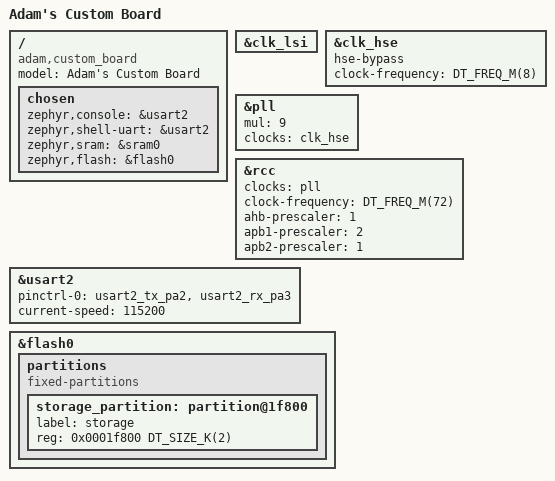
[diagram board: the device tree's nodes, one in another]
/dts-v1/;
#include <st/f1/stm32f103Xb.dtsi>
#include <st/f1/stm32f103r(8-b)tx-pinctrl.dtsi>
#include <zephyr/dt-bindings/input/input-event-codes.h>

/ {
	model = "Adam's Custom Board";
    compatible = "adam,custom_board";

	chosen {
        zephyr,console = &usart2;
		zephyr,shell-uart = &usart2;
		zephyr,sram = &sram0;
		zephyr,flash = &flash0;
	};
};

&clk_lsi {
	status = "okay";
};

&clk_hse {
	hse-bypass;
	clock-frequency = <DT_FREQ_M(8)>;
	status = "okay";
};

&pll {
	mul = <9>;
	clocks = <&clk_hse>;
	status = "okay";
};

&rcc {
	clocks = <&pll>;
	clock-frequency = <DT_FREQ_M(72)>;
	ahb-prescaler = <1>;
	apb1-prescaler = <2>;
	apb2-prescaler = <1>;
};

&usart2 {
	pinctrl-0 = <&usart2_tx_pa2 &usart2_rx_pa3>;
	pinctrl-names = "default";
	current-speed = <115200>;
	status = "okay";
};

&flash0 {
	partitions {
		compatible = "fixed-partitions";
		#address-cells = <1>;
		#size-cells = <1>;

		/* Set 2KB of storage at the end of 128KB flash */
		storage_partition: partition@1f800 {
			label = "storage";
			reg = <0x0001f800 DT_SIZE_K(2)>;
		};
	};
};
